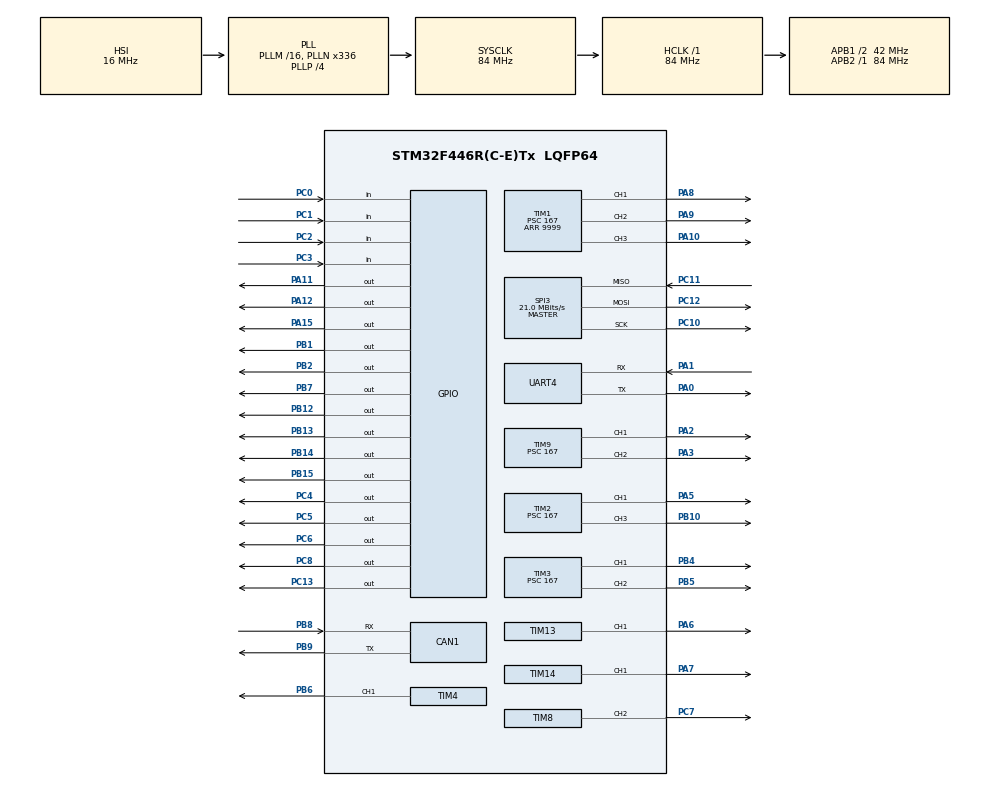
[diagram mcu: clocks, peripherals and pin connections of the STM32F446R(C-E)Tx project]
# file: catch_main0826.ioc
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CAN1.CalculateTimeQuantum=380.95238095238096
Mcu.Family=STM32F4
Mcu.Name=STM32F446R(C-E)Tx
Mcu.Package=LQFP64
NVIC.PriorityGroup=NVIC_PRIORITYGROUP_0
PA0-WKUP.Mode=Asynchronous
PA0-WKUP.Signal=UART4_TX
PA1.Mode=Asynchronous
PA1.Signal=UART4_RX
PA10.Signal=S_TIM1_CH3
PA11.Signal=GPIO_Output
PA12.Signal=GPIO_Output
PA13.Mode=Serial_Wire
PA13.Signal=SYS_JTMS-SWDIO
PA14.GPIO_Label=TCK
PA14.Mode=Serial_Wire
PA14.Signal=SYS_JTCK-SWCLK
PA15.Signal=GPIO_Output
PA2.Signal=S_TIM9_CH1
PA3.Signal=S_TIM9_CH2
PA5.Signal=S_TIM2_CH1_ETR
PA6.Signal=S_TIM13_CH1
PA7.Signal=S_TIM14_CH1
PA8.Signal=S_TIM1_CH1
PA9.Signal=S_TIM1_CH2
PB1.Signal=GPIO_Output
PB10.Signal=S_TIM2_CH3
PB12.Signal=GPIO_Output
PB13.Signal=GPIO_Output
PB14.Signal=GPIO_Output
PB15.Signal=GPIO_Output
PB2.Signal=GPIO_Output
PB3.GPIO_Label=SWO
PB3.Signal=SYS_JTDO-SWO
PB4.Signal=S_TIM3_CH1
PB5.Signal=S_TIM3_CH2
PB6.Signal=S_TIM4_CH1
PB7.Signal=GPIO_Output
PB8.Mode=Master
PB8.Signal=CAN1_RX
PB9.Mode=Master
PB9.Signal=CAN1_TX
PC0.Signal=GPIO_Input
PC1.Signal=GPIO_Input
PC10.Mode=Full_Duplex_Master
PC10.Signal=SPI3_SCK
PC11.Mode=Full_Duplex_Master
PC11.Signal=SPI3_MISO
PC12.Mode=Full_Duplex_Master
PC12.Signal=SPI3_MOSI
PC13.Signal=GPIO_Output
PC14-OSC32_IN.Mode=LSE-External-Oscillator
PC14-OSC32_IN.Signal=RCC_OSC32_IN
PC15-OSC32_OUT.Mode=LSE-External-Oscillator
PC15-OSC32_OUT.Signal=RCC_OSC32_OUT
PC2.Signal=GPIO_Input
PC3.Signal=GPIO_Input
PC4.Signal=GPIO_Output
PC5.Signal=GPIO_Output
PC6.Signal=GPIO_Output
PC7.Signal=S_TIM8_CH2
PC8.Signal=GPIO_Output
PH0-OSC_IN.Mode=HSE-External-Oscillator
PH0-OSC_IN.Signal=RCC_OSC_IN
PH1-OSC_OUT.Mode=HSE-External-Oscillator
PH1-OSC_OUT.Signal=RCC_OSC_OUT
ProjectManager.HeapSize=0x200
ProjectManager.StackSize=0x400
ProjectManager.TargetToolchain=SW4STM32
RCC.48MHZClocksFreq_Value=84000000
RCC.AHBFreq_Value=84000000
RCC.APB1CLKDivider=RCC_HCLK_DIV2
RCC.APB1Freq_Value=42000000
RCC.APB1TimFreq_Value=84000000
RCC.APB2Freq_Value=84000000
RCC.APB2TimFreq_Value=84000000
RCC.CortexFreq_Value=84000000
RCC.FLatency-AdvancedSettings=FLASH_LATENCY_2
RCC.HCLKFreq_Value=84000000
RCC.HSE_VALUE=8000000
RCC.HSI_VALUE=16000000
RCC.PLLN=336
RCC.PLLP=RCC_PLLP_DIV4
RCC.SYSCLKFreq_VALUE=84000000
RCC.SYSCLKSource=RCC_SYSCLKSOURCE_PLLCLK
RCC.USBFreq_Value=168000000
RCC.VCOOutputFreq_Value=336000000
SH.S_TIM13_CH1.0=TIM13_CH1,PWM Generation1 CH1
SH.S_TIM14_CH1.0=TIM14_CH1,PWM Generation1 CH1
SH.S_TIM1_CH1.0=TIM1_CH1,PWM Generation1 CH1
SH.S_TIM1_CH2.0=TIM1_CH2,PWM Generation2 CH2
SH.S_TIM1_CH3.0=TIM1_CH3,PWM Generation3 CH3
SH.S_TIM2_CH1_ETR.0=TIM2_CH1,PWM Generation1 CH1
SH.S_TIM2_CH3.0=TIM2_CH3,PWM Generation3 CH3
SH.S_TIM3_CH1.0=TIM3_CH1,PWM Generation1 CH1
SH.S_TIM3_CH2.0=TIM3_CH2,PWM Generation2 CH2
SH.S_TIM4_CH1.0=TIM4_CH1,PWM Generation1 CH1
SH.S_TIM8_CH2.0=TIM8_CH2,PWM Generation2 CH2
SH.S_TIM9_CH1.0=TIM9_CH1,PWM Generation1 CH1
SH.S_TIM9_CH2.0=TIM9_CH2,PWM Generation2 CH2
SPI3.CalculateBaudRate=21.0 MBits/s
SPI3.Direction=SPI_DIRECTION_2LINES
SPI3.Mode=SPI_MODE_MASTER
SPI3.VirtualType=VM_MASTER
TIM1.Channel-PWM\ Generation1\ CH1=TIM_CHANNEL_1
TIM1.Channel-PWM\ Generation2\ CH2=TIM_CHANNEL_2
TIM1.Channel-PWM\ Generation3\ CH3=TIM_CHANNEL_3
TIM1.Period=9999
TIM1.Prescaler=167
TIM13.Channel=TIM_CHANNEL_1
TIM13.Period=9999
TIM13.Prescaler=167
TIM14.Channel=TIM_CHANNEL_1
TIM14.Period=9999
TIM14.Prescaler=167
TIM2.Channel-PWM\ Generation1\ CH1=TIM_CHANNEL_1
TIM2.Channel-PWM\ Generation3\ CH3=TIM_CHANNEL_3
TIM2.Period=9999
TIM2.Prescaler=167
TIM3.Channel-PWM\ Generation1\ CH1=TIM_CHANNEL_1
TIM3.Channel-PWM\ Generation2\ CH2=TIM_CHANNEL_2
TIM3.Period=9999
TIM3.Prescaler=167
TIM4.Channel-PWM\ Generation1\ CH1=TIM_CHANNEL_1
TIM4.Channel-PWM\ Generation3\ CH3=TIM_CHANNEL_3
TIM4.Channel-PWM\ Generation4\ CH4=TIM_CHANNEL_4
TIM4.Period=9999
TIM4.Prescaler=167
TIM8.Channel-PWM\ Generation2\ CH2=TIM_CHANNEL_2
TIM8.Period=9999
TIM8.Prescaler=167
TIM9.Channel-PWM\ Generation1\ CH1=TIM_CHANNEL_1
TIM9.Channel-PWM\ Generation2\ CH2=TIM_CHANNEL_2
TIM9.Period=9999
TIM9.Prescaler=167
UART4.VirtualMode=Asynchronous
VP_TIM13_VS_ClockSourceINT.Mode=Enable_Timer
VP_TIM14_VS_ClockSourceINT.Mode=Enable_Timer
VP_TIM1_VS_ClockSourceINT.Mode=Internal
board=NUCLEO-F446RE

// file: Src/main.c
/* USER CODE BEGIN Header */
/**
  ******************************************************************************
  * @file           : main.c
  * @brief          : Main program body
  ******************************************************************************
  * @attention
  *
  * <h2><center>&copy; Copyright (c) 2019 STMicroelectronics.
  * All rights reserved.</center></h2>
  *
  * This software component is licensed by ST under BSD 3-Clause license,
  * the "License"; You may not use this file except in compliance with the
  * License. You may obtain a copy of the License at:
  *                        opensource.org/licenses/BSD-3-Clause
  *
  ******************************************************************************
  */
/* USER CODE END Header */

#include "main.h"

/* USER CODE BEGIN Includes */
#include "servomotor.h"
#include "stm32f4xx_hal.h"
/* USER CODE END Includes */

CAN_HandleTypeDef hcan1;

SPI_HandleTypeDef hspi3;

TIM_HandleTypeDef htim1;
TIM_HandleTypeDef htim2;
TIM_HandleTypeDef htim3;
TIM_HandleTypeDef htim4;
TIM_HandleTypeDef htim8;
TIM_HandleTypeDef htim9;
TIM_HandleTypeDef htim13;
TIM_HandleTypeDef htim14;

UART_HandleTypeDef huart4;

/* USER CODE BEGIN PV */
int angle = 0;

TIM_MasterConfigTypeDef sMasterConfig = {0};
TIM_OC_InitTypeDef sConfigOC = {0};
/* USER CODE END PV */

void SystemClock_Config(void);
static void MX_GPIO_Init(void);
static void MX_CAN1_Init(void);
static void MX_SPI3_Init(void);
static void MX_TIM1_Init(void);
static void MX_TIM2_Init(void);
static void MX_TIM3_Init(void);
static void MX_TIM4_Init(void);
static void MX_TIM8_Init(void);
static void MX_TIM9_Init(void);
static void MX_TIM13_Init(void);
static void MX_TIM14_Init(void);
static void MX_UART4_Init(void);

int main(void)
{

  /* MCU Configuration--------------------------------------------------------*/

  /* Reset of all peripherals, Initializes the Flash interface and the Systick. */
  HAL_Init();

  /* Configure the system clock */
  SystemClock_Config();

  /* Initialize all configured peripherals */
  MX_GPIO_Init();
  MX_CAN1_Init();
  MX_SPI3_Init();
  MX_TIM1_Init();
  MX_TIM2_Init();
  MX_TIM3_Init();
  MX_TIM4_Init();
  MX_TIM8_Init();
  MX_TIM9_Init();
  MX_TIM13_Init();
  MX_TIM14_Init();
  MX_UART4_Init();
  /* USER CODE BEGIN 2 */
  /*ServoEnable();

  angle = 10;

  HAL_Delay(300);

  ServoSetAngle(angle);

  HAL_Delay(300);

  ServoDisable();

*/
//  HAL_TIM_PWM_Start(&SERVO1_TIM_HANDLER, SERVO1_TIM_CH);
/*
  if(HAL_TIM_PWM_Start(&htim3,TIM_CHANNEL_1)!=HAL_OK){
  	  Error_Handler();
    }
  __HAL_TIM_SET_COMPARE(&htim3,TIM_CHANNEL_1,750);
  */
  sConfigOC.Pulse = 750;
  if (HAL_TIM_PWM_ConfigChannel(&htim3, &sConfigOC, TIM_CHANNEL_2) != HAL_OK)
 	  {
 	  Error_Handler();
   }
   if (HAL_TIM_PWM_Start(&htim3, TIM_CHANNEL_2) != HAL_OK)
   {
 	  Error_Handler();
   }
  /* USER CODE END 2 */

  /* Infinite loop */
  while (1)
  {

  }
}

void SystemClock_Config(void)
{
  RCC_OscInitTypeDef RCC_OscInitStruct = {0};
  RCC_ClkInitTypeDef RCC_ClkInitStruct = {0};

  /** Configure the main internal regulator output voltage
  */
  __HAL_RCC_PWR_CLK_ENABLE();
  __HAL_PWR_VOLTAGESCALING_CONFIG(PWR_REGULATOR_VOLTAGE_SCALE3);
  /** Initializes the CPU, AHB and APB busses clocks
  */
  RCC_OscInitStruct.OscillatorType = RCC_OSCILLATORTYPE_HSI;
  RCC_OscInitStruct.HSIState = RCC_HSI_ON;
  RCC_OscInitStruct.HSICalibrationValue = RCC_HSICALIBRATION_DEFAULT;
  RCC_OscInitStruct.PLL.PLLState = RCC_PLL_ON;
  RCC_OscInitStruct.PLL.PLLSource = RCC_PLLSOURCE_HSI;
  RCC_OscInitStruct.PLL.PLLM = 16;
  RCC_OscInitStruct.PLL.PLLN = 336;
  RCC_OscInitStruct.PLL.PLLP = RCC_PLLP_DIV4;
  RCC_OscInitStruct.PLL.PLLQ = 2;
  RCC_OscInitStruct.PLL.PLLR = 2;
  if (HAL_RCC_OscConfig(&RCC_OscInitStruct) != HAL_OK)
  {
    Error_Handler();
  }
  /** Initializes the CPU, AHB and APB busses clocks
  */
  RCC_ClkInitStruct.ClockType = RCC_CLOCKTYPE_HCLK|RCC_CLOCKTYPE_SYSCLK
                              |RCC_CLOCKTYPE_PCLK1|RCC_CLOCKTYPE_PCLK2;
  RCC_ClkInitStruct.SYSCLKSource = RCC_SYSCLKSOURCE_PLLCLK;
  RCC_ClkInitStruct.AHBCLKDivider = RCC_SYSCLK_DIV1;
  RCC_ClkInitStruct.APB1CLKDivider = RCC_HCLK_DIV2;
  RCC_ClkInitStruct.APB2CLKDivider = RCC_HCLK_DIV1;

  if (HAL_RCC_ClockConfig(&RCC_ClkInitStruct, FLASH_LATENCY_2) != HAL_OK)
  {
    Error_Handler();
  }
}

static void MX_CAN1_Init(void)
{

  hcan1.Instance = CAN1;
  hcan1.Init.Prescaler = 16;
  hcan1.Init.Mode = CAN_MODE_NORMAL;
  hcan1.Init.SyncJumpWidth = CAN_SJW_1TQ;
  hcan1.Init.TimeSeg1 = CAN_BS1_1TQ;
  hcan1.Init.TimeSeg2 = CAN_BS2_1TQ;
  hcan1.Init.TimeTriggeredMode = DISABLE;
  hcan1.Init.AutoBusOff = DISABLE;
  hcan1.Init.AutoWakeUp = DISABLE;
  hcan1.Init.AutoRetransmission = DISABLE;
  hcan1.Init.ReceiveFifoLocked = DISABLE;
  hcan1.Init.TransmitFifoPriority = DISABLE;
  if (HAL_CAN_Init(&hcan1) != HAL_OK)
  {
    Error_Handler();
  }

}

static void MX_SPI3_Init(void)
{

  /* SPI3 parameter configuration*/
  hspi3.Instance = SPI3;
  hspi3.Init.Mode = SPI_MODE_MASTER;
  hspi3.Init.Direction = SPI_DIRECTION_2LINES;
  hspi3.Init.DataSize = SPI_DATASIZE_8BIT;
  hspi3.Init.CLKPolarity = SPI_POLARITY_LOW;
  hspi3.Init.CLKPhase = SPI_PHASE_1EDGE;
  hspi3.Init.NSS = SPI_NSS_SOFT;
  hspi3.Init.BaudRatePrescaler = SPI_BAUDRATEPRESCALER_2;
  hspi3.Init.FirstBit = SPI_FIRSTBIT_MSB;
  hspi3.Init.TIMode = SPI_TIMODE_DISABLE;
  hspi3.Init.CRCCalculation = SPI_CRCCALCULATION_DISABLE;
  hspi3.Init.CRCPolynomial = 10;
  if (HAL_SPI_Init(&hspi3) != HAL_OK)
  {
    Error_Handler();
  }

}

static void MX_TIM1_Init(void)
{

  TIM_ClockConfigTypeDef sClockSourceConfig = {0};
  TIM_MasterConfigTypeDef sMasterConfig = {0};
  TIM_OC_InitTypeDef sConfigOC = {0};
  TIM_BreakDeadTimeConfigTypeDef sBreakDeadTimeConfig = {0};

  htim1.Instance = TIM1;
  htim1.Init.Prescaler = 167;
  htim1.Init.CounterMode = TIM_COUNTERMODE_UP;
  htim1.Init.Period = 9999;
  htim1.Init.ClockDivision = TIM_CLOCKDIVISION_DIV1;
  htim1.Init.RepetitionCounter = 0;
  htim1.Init.AutoReloadPreload = TIM_AUTORELOAD_PRELOAD_DISABLE;
  if (HAL_TIM_Base_Init(&htim1) != HAL_OK)
  {
    Error_Handler();
  }
  sClockSourceConfig.ClockSource = TIM_CLOCKSOURCE_INTERNAL;
  if (HAL_TIM_ConfigClockSource(&htim1, &sClockSourceConfig) != HAL_OK)
  {
    Error_Handler();
  }
  if (HAL_TIM_PWM_Init(&htim1) != HAL_OK)
  {
    Error_Handler();
  }
  sMasterConfig.MasterOutputTrigger = TIM_TRGO_RESET;
  sMasterConfig.MasterSlaveMode = TIM_MASTERSLAVEMODE_DISABLE;
  if (HAL_TIMEx_MasterConfigSynchronization(&htim1, &sMasterConfig) != HAL_OK)
  {
    Error_Handler();
  }
  sConfigOC.OCMode = TIM_OCMODE_PWM1;
  sConfigOC.Pulse = 0;
  sConfigOC.OCPolarity = TIM_OCPOLARITY_HIGH;
  sConfigOC.OCNPolarity = TIM_OCNPOLARITY_HIGH;
  sConfigOC.OCFastMode = TIM_OCFAST_DISABLE;
  sConfigOC.OCIdleState = TIM_OCIDLESTATE_RESET;
  sConfigOC.OCNIdleState = TIM_OCNIDLESTATE_RESET;
  if (HAL_TIM_PWM_ConfigChannel(&htim1, &sConfigOC, TIM_CHANNEL_1) != HAL_OK)
  {
    Error_Handler();
  }
  if (HAL_TIM_PWM_ConfigChannel(&htim1, &sConfigOC, TIM_CHANNEL_2) != HAL_OK)
  {
    Error_Handler();
  }
  if (HAL_TIM_PWM_ConfigChannel(&htim1, &sConfigOC, TIM_CHANNEL_3) != HAL_OK)
  {
    Error_Handler();
  }
  sBreakDeadTimeConfig.OffStateRunMode = TIM_OSSR_DISABLE;
  sBreakDeadTimeConfig.OffStateIDLEMode = TIM_OSSI_DISABLE;
  sBreakDeadTimeConfig.LockLevel = TIM_LOCKLEVEL_OFF;
  sBreakDeadTimeConfig.DeadTime = 0;
  sBreakDeadTimeConfig.BreakState = TIM_BREAK_DISABLE;
  sBreakDeadTimeConfig.BreakPolarity = TIM_BREAKPOLARITY_HIGH;
  sBreakDeadTimeConfig.AutomaticOutput = TIM_AUTOMATICOUTPUT_DISABLE;
  if (HAL_TIMEx_ConfigBreakDeadTime(&htim1, &sBreakDeadTimeConfig) != HAL_OK)
  {
    Error_Handler();
  }
  HAL_TIM_MspPostInit(&htim1);

}

static void MX_TIM2_Init(void)
{

  TIM_MasterConfigTypeDef sMasterConfig = {0};
  TIM_OC_InitTypeDef sConfigOC = {0};

  htim2.Instance = TIM2;
  htim2.Init.Prescaler = 167;
  htim2.Init.CounterMode = TIM_COUNTERMODE_UP;
  htim2.Init.Period = 9999;
  htim2.Init.ClockDivision = TIM_CLOCKDIVISION_DIV1;
  htim2.Init.AutoReloadPreload = TIM_AUTORELOAD_PRELOAD_DISABLE;
  if (HAL_TIM_PWM_Init(&htim2) != HAL_OK)
  {
    Error_Handler();
  }
  sMasterConfig.MasterOutputTrigger = TIM_TRGO_RESET;
  sMasterConfig.MasterSlaveMode = TIM_MASTERSLAVEMODE_DISABLE;
  if (HAL_TIMEx_MasterConfigSynchronization(&htim2, &sMasterConfig) != HAL_OK)
  {
    Error_Handler();
  }
  sConfigOC.OCMode = TIM_OCMODE_PWM1;
  sConfigOC.Pulse = 0;
  sConfigOC.OCPolarity = TIM_OCPOLARITY_HIGH;
  sConfigOC.OCFastMode = TIM_OCFAST_DISABLE;
  if (HAL_TIM_PWM_ConfigChannel(&htim2, &sConfigOC, TIM_CHANNEL_1) != HAL_OK)
  {
    Error_Handler();
  }
  if (HAL_TIM_PWM_ConfigChannel(&htim2, &sConfigOC, TIM_CHANNEL_3) != HAL_OK)
  {
    Error_Handler();
  }
  HAL_TIM_MspPostInit(&htim2);

}

static void MX_TIM3_Init(void)
{

  htim3.Instance = TIM3;
  htim3.Init.Prescaler = 167;
  htim3.Init.CounterMode = TIM_COUNTERMODE_UP;
  htim3.Init.Period = 9999;
  htim3.Init.ClockDivision = TIM_CLOCKDIVISION_DIV1;
  htim3.Init.AutoReloadPreload = TIM_AUTORELOAD_PRELOAD_DISABLE;
  if (HAL_TIM_PWM_Init(&htim3) != HAL_OK)
  {
    Error_Handler();
  }
  sMasterConfig.MasterOutputTrigger = TIM_TRGO_RESET;
  sMasterConfig.MasterSlaveMode = TIM_MASTERSLAVEMODE_DISABLE;
  if (HAL_TIMEx_MasterConfigSynchronization(&htim3, &sMasterConfig) != HAL_OK)
  {
    Error_Handler();
  }
  sConfigOC.OCMode = TIM_OCMODE_PWM1;
  sConfigOC.Pulse = 0;
  sConfigOC.OCPolarity = TIM_OCPOLARITY_HIGH;
  sConfigOC.OCFastMode = TIM_OCFAST_DISABLE;
  if (HAL_TIM_PWM_ConfigChannel(&htim3, &sConfigOC, TIM_CHANNEL_1) != HAL_OK)
  {
    Error_Handler();
  }
  if (HAL_TIM_PWM_ConfigChannel(&htim3, &sConfigOC, TIM_CHANNEL_2) != HAL_OK)
  {
    Error_Handler();
  }
  HAL_TIM_MspPostInit(&htim3);

}

static void MX_TIM4_Init(void)
{

  TIM_MasterConfigTypeDef sMasterConfig = {0};
  TIM_OC_InitTypeDef sConfigOC = {0};

  htim4.Instance = TIM4;
  htim4.Init.Prescaler = 167;
  htim4.Init.CounterMode = TIM_COUNTERMODE_UP;
  htim4.Init.Period = 9999;
  htim4.Init.ClockDivision = TIM_CLOCKDIVISION_DIV1;
  htim4.Init.AutoReloadPreload = TIM_AUTORELOAD_PRELOAD_DISABLE;
  if (HAL_TIM_PWM_Init(&htim4) != HAL_OK)
  {
    Error_Handler();
  }
  sMasterConfig.MasterOutputTrigger = TIM_TRGO_RESET;
  sMasterConfig.MasterSlaveMode = TIM_MASTERSLAVEMODE_DISABLE;
  if (HAL_TIMEx_MasterConfigSynchronization(&htim4, &sMasterConfig) != HAL_OK)
  {
    Error_Handler();
  }
  sConfigOC.OCMode = TIM_OCMODE_PWM1;
  sConfigOC.Pulse = 0;
  sConfigOC.OCPolarity = TIM_OCPOLARITY_HIGH;
  sConfigOC.OCFastMode = TIM_OCFAST_DISABLE;
  if (HAL_TIM_PWM_ConfigChannel(&htim4, &sConfigOC, TIM_CHANNEL_1) != HAL_OK)
  {
    Error_Handler();
  }
  HAL_TIM_MspPostInit(&htim4);

}

static void MX_TIM8_Init(void)
{

  TIM_MasterConfigTypeDef sMasterConfig = {0};
  TIM_OC_InitTypeDef sConfigOC = {0};
  TIM_BreakDeadTimeConfigTypeDef sBreakDeadTimeConfig = {0};

  htim8.Instance = TIM8;
  htim8.Init.Prescaler = 167;
  htim8.Init.CounterMode = TIM_COUNTERMODE_UP;
  htim8.Init.Period = 9999;
  htim8.Init.ClockDivision = TIM_CLOCKDIVISION_DIV1;
  htim8.Init.RepetitionCounter = 0;
  htim8.Init.AutoReloadPreload = TIM_AUTORELOAD_PRELOAD_DISABLE;
  if (HAL_TIM_PWM_Init(&htim8) != HAL_OK)
  {
    Error_Handler();
  }
  sMasterConfig.MasterOutputTrigger = TIM_TRGO_RESET;
  sMasterConfig.MasterSlaveMode = TIM_MASTERSLAVEMODE_DISABLE;
  if (HAL_TIMEx_MasterConfigSynchronization(&htim8, &sMasterConfig) != HAL_OK)
  {
    Error_Handler();
  }
  sConfigOC.OCMode = TIM_OCMODE_PWM1;
  sConfigOC.Pulse = 0;
  sConfigOC.OCPolarity = TIM_OCPOLARITY_HIGH;
  sConfigOC.OCNPolarity = TIM_OCNPOLARITY_HIGH;
  sConfigOC.OCFastMode = TIM_OCFAST_DISABLE;
  sConfigOC.OCIdleState = TIM_OCIDLESTATE_RESET;
  sConfigOC.OCNIdleState = TIM_OCNIDLESTATE_RESET;
  if (HAL_TIM_PWM_ConfigChannel(&htim8, &sConfigOC, TIM_CHANNEL_2) != HAL_OK)
  {
    Error_Handler();
  }
  sBreakDeadTimeConfig.OffStateRunMode = TIM_OSSR_DISABLE;
  sBreakDeadTimeConfig.OffStateIDLEMode = TIM_OSSI_DISABLE;
  sBreakDeadTimeConfig.LockLevel = TIM_LOCKLEVEL_OFF;
  sBreakDeadTimeConfig.DeadTime = 0;
  sBreakDeadTimeConfig.BreakState = TIM_BREAK_DISABLE;
  sBreakDeadTimeConfig.BreakPolarity = TIM_BREAKPOLARITY_HIGH;
  sBreakDeadTimeConfig.AutomaticOutput = TIM_AUTOMATICOUTPUT_DISABLE;
  if (HAL_TIMEx_ConfigBreakDeadTime(&htim8, &sBreakDeadTimeConfig) != HAL_OK)
  {
    Error_Handler();
  }
  HAL_TIM_MspPostInit(&htim8);

}

static void MX_TIM9_Init(void)
{

  TIM_OC_InitTypeDef sConfigOC = {0};

  htim9.Instance = TIM9;
  htim9.Init.Prescaler = 167;
  htim9.Init.CounterMode = TIM_COUNTERMODE_UP;
  htim9.Init.Period = 9999;
  htim9.Init.ClockDivision = TIM_CLOCKDIVISION_DIV1;
  htim9.Init.AutoReloadPreload = TIM_AUTORELOAD_PRELOAD_DISABLE;
  if (HAL_TIM_PWM_Init(&htim9) != HAL_OK)
  {
    Error_Handler();
  }
  sConfigOC.OCMode = TIM_OCMODE_PWM1;
  sConfigOC.Pulse = 0;
  sConfigOC.OCPolarity = TIM_OCPOLARITY_HIGH;
  sConfigOC.OCFastMode = TIM_OCFAST_DISABLE;
  if (HAL_TIM_PWM_ConfigChannel(&htim9, &sConfigOC, TIM_CHANNEL_1) != HAL_OK)
  {
    Error_Handler();
  }
  if (HAL_TIM_PWM_ConfigChannel(&htim9, &sConfigOC, TIM_CHANNEL_2) != HAL_OK)
  {
    Error_Handler();
  }
  HAL_TIM_MspPostInit(&htim9);

}

static void MX_TIM13_Init(void)
{

  TIM_OC_InitTypeDef sConfigOC = {0};

  htim13.Instance = TIM13;
  htim13.Init.Prescaler = 167;
  htim13.Init.CounterMode = TIM_COUNTERMODE_UP;
  htim13.Init.Period = 9999;
  htim13.Init.ClockDivision = TIM_CLOCKDIVISION_DIV1;
  htim13.Init.AutoReloadPreload = TIM_AUTORELOAD_PRELOAD_DISABLE;
  if (HAL_TIM_Base_Init(&htim13) != HAL_OK)
  {
    Error_Handler();
  }
  if (HAL_TIM_PWM_Init(&htim13) != HAL_OK)
  {
    Error_Handler();
  }
  sConfigOC.OCMode = TIM_OCMODE_PWM1;
  sConfigOC.Pulse = 0;
  sConfigOC.OCPolarity = TIM_OCPOLARITY_HIGH;
  sConfigOC.OCFastMode = TIM_OCFAST_DISABLE;
  if (HAL_TIM_PWM_ConfigChannel(&htim13, &sConfigOC, TIM_CHANNEL_1) != HAL_OK)
  {
    Error_Handler();
  }
  HAL_TIM_MspPostInit(&htim13);

}

static void MX_TIM14_Init(void)
{

  TIM_OC_InitTypeDef sConfigOC = {0};

  htim14.Instance = TIM14;
  htim14.Init.Prescaler = 167;
  htim14.Init.CounterMode = TIM_COUNTERMODE_UP;
  htim14.Init.Period = 9999;
  htim14.Init.ClockDivision = TIM_CLOCKDIVISION_DIV1;
  htim14.Init.AutoReloadPreload = TIM_AUTORELOAD_PRELOAD_DISABLE;
  if (HAL_TIM_Base_Init(&htim14) != HAL_OK)
  {
    Error_Handler();
  }
  if (HAL_TIM_PWM_Init(&htim14) != HAL_OK)
  {
    Error_Handler();
  }
  sConfigOC.OCMode = TIM_OCMODE_PWM1;
  sConfigOC.Pulse = 0;
  sConfigOC.OCPolarity = TIM_OCPOLARITY_HIGH;
  sConfigOC.OCFastMode = TIM_OCFAST_DISABLE;
  if (HAL_TIM_PWM_ConfigChannel(&htim14, &sConfigOC, TIM_CHANNEL_1) != HAL_OK)
  {
    Error_Handler();
  }
  HAL_TIM_MspPostInit(&htim14);

}

static void MX_UART4_Init(void)
{

  huart4.Instance = UART4;
  huart4.Init.BaudRate = 115200;
  huart4.Init.WordLength = UART_WORDLENGTH_8B;
  huart4.Init.StopBits = UART_STOPBITS_1;
  huart4.Init.Parity = UART_PARITY_NONE;
  huart4.Init.Mode = UART_MODE_TX_RX;
  huart4.Init.HwFlowCtl = UART_HWCONTROL_NONE;
  huart4.Init.OverSampling = UART_OVERSAMPLING_16;
  if (HAL_UART_Init(&huart4) != HAL_OK)
  {
    Error_Handler();
  }

}

static void MX_GPIO_Init(void)
{
  GPIO_InitTypeDef GPIO_InitStruct = {0};

  /* GPIO Ports Clock Enable */
  __HAL_RCC_GPIOC_CLK_ENABLE();
  __HAL_RCC_GPIOH_CLK_ENABLE();
  __HAL_RCC_GPIOA_CLK_ENABLE();
  __HAL_RCC_GPIOB_CLK_ENABLE();

  /*Configure GPIO pin Output Level */
  HAL_GPIO_WritePin(GPIOC, GPIO_PIN_13|GPIO_PIN_4|GPIO_PIN_5|GPIO_PIN_6
                          |GPIO_PIN_8, GPIO_PIN_RESET);

  /*Configure GPIO pin Output Level */
  HAL_GPIO_WritePin(GPIOB, GPIO_PIN_1|GPIO_PIN_2|GPIO_PIN_12|GPIO_PIN_13
                          |GPIO_PIN_14|GPIO_PIN_15|GPIO_PIN_7, GPIO_PIN_RESET);

  /*Configure GPIO pin Output Level */
  HAL_GPIO_WritePin(GPIOA, GPIO_PIN_11|GPIO_PIN_12|GPIO_PIN_15, GPIO_PIN_RESET);

  /*Configure GPIO pins : PC13 PC4 PC5 PC6
                           PC8 */
  GPIO_InitStruct.Pin = GPIO_PIN_13|GPIO_PIN_4|GPIO_PIN_5|GPIO_PIN_6
                          |GPIO_PIN_8;
  GPIO_InitStruct.Mode = GPIO_MODE_OUTPUT_PP;
  GPIO_InitStruct.Pull = GPIO_NOPULL;
  GPIO_InitStruct.Speed = GPIO_SPEED_FREQ_LOW;
  HAL_GPIO_Init(GPIOC, &GPIO_InitStruct);

  /*Configure GPIO pins : PC0 PC1 PC2 PC3 */
  GPIO_InitStruct.Pin = GPIO_PIN_0|GPIO_PIN_1|GPIO_PIN_2|GPIO_PIN_3;
  GPIO_InitStruct.Mode = GPIO_MODE_INPUT;
  GPIO_InitStruct.Pull = GPIO_NOPULL;
  HAL_GPIO_Init(GPIOC, &GPIO_InitStruct);

  /*Configure GPIO pins : PB1 PB2 PB12 PB13
                           PB14 PB15 PB7 */
  GPIO_InitStruct.Pin = GPIO_PIN_1|GPIO_PIN_2|GPIO_PIN_12|GPIO_PIN_13
                          |GPIO_PIN_14|GPIO_PIN_15|GPIO_PIN_7;
  GPIO_InitStruct.Mode = GPIO_MODE_OUTPUT_PP;
  GPIO_InitStruct.Pull = GPIO_NOPULL;
  GPIO_InitStruct.Speed = GPIO_SPEED_FREQ_LOW;
  HAL_GPIO_Init(GPIOB, &GPIO_InitStruct);

  /*Configure GPIO pins : PA11 PA12 PA15 */
  GPIO_InitStruct.Pin = GPIO_PIN_11|GPIO_PIN_12|GPIO_PIN_15;
  GPIO_InitStruct.Mode = GPIO_MODE_OUTPUT_PP;
  GPIO_InitStruct.Pull = GPIO_NOPULL;
  GPIO_InitStruct.Speed = GPIO_SPEED_FREQ_LOW;
  HAL_GPIO_Init(GPIOA, &GPIO_InitStruct);

}

void Error_Handler(void)
{
}

/************************ (C) COPYRIGHT STMicroelectronics *****END OF FILE****/
